VERSION ""

NS_ :

BS_:

BU_: NUC IPC VCU ADCU Mobileye Instrumentation Vehicle ESR
VAL_TABLE_ VtSIg_eventState_9 9 "caution-Conflicting-Traffic" 8 "protected-clearance : yellow" 7 "permissive-clearance" 6 "protected-Movement-Allowed" 5 "permissive-Movement-Allowed" 4 "pre-Movement : red+yellow partly" 3 "stop-And-Remain : red right" 2 "stop-Then-Proceed : flashing red" 1 "dark" 0 "unavailable" ;
VAL_TABLE_ VtSIg_eventState_8 9 "caution-Conflicting-Traffic" 8 "protected-clearance : yellow" 7 "permissive-clearance" 6 "protected-Movement-Allowed" 5 "permissive-Movement-Allowed" 4 "pre-Movement : red+yellow partly" 3 "stop-And-Remain : red right" 2 "stop-Then-Proceed : flashing red" 1 "dark" 0 "unavailable" ;
VAL_TABLE_ VtSIg_eventState_7 9 "caution-Conflicting-Traffic" 8 "protected-clearance : yellow" 7 "permissive-clearance" 6 "protected-Movement-Allowed" 5 "permissive-Movement-Allowed" 4 "pre-Movement : red+yellow partly" 3 "stop-And-Remain : red right" 2 "stop-Then-Proceed : flashing red" 1 "dark" 0 "unavailable" ;
VAL_TABLE_ VtSIg_eventState_6 9 "caution-Conflicting-Traffic" 8 "protected-clearance : yellow" 7 "permissive-clearance" 6 "protected-Movement-Allowed" 5 "permissive-Movement-Allowed" 4 "pre-Movement : red+yellow partly" 3 "stop-And-Remain : red right" 2 "stop-Then-Proceed : flashing red" 1 "dark" 0 "unavailable" ;
VAL_TABLE_ VtSIg_eventState_5 9 "caution-Conflicting-Traffic" 8 "protected-clearance : yellow" 7 "permissive-clearance" 6 "protected-Movement-Allowed" 5 "permissive-Movement-Allowed" 4 "pre-Movement : red+yellow partly" 3 "stop-And-Remain : red right" 2 "stop-Then-Proceed : flashing red" 1 "dark" 0 "unavailable" ;
VAL_TABLE_ VtSIg_eventState_4 9 "caution-Conflicting-Traffic" 8 "protected-clearance : yellow" 7 "permissive-clearance" 6 "protected-Movement-Allowed" 5 "permissive-Movement-Allowed" 4 "pre-Movement : red+yellow partly" 3 "stop-And-Remain : red right" 2 "stop-Then-Proceed : flashing red" 1 "dark" 0 "unavailable" ;
VAL_TABLE_ VtSIg_eventState_3 9 "caution-Conflicting-Traffic" 8 "protected-clearance : yellow" 7 "permissive-clearance" 6 "protected-Movement-Allowed" 5 "permissive-Movement-Allowed" 4 "pre-Movement : red+yellow partly" 3 "stop-And-Remain : red right" 2 "stop-Then-Proceed : flashing red" 1 "dark" 0 "unavailable" ;
VAL_TABLE_ VtSIg_eventState_2 9 "caution-Conflicting-Traffic" 8 "protected-clearance : yellow" 7 "permissive-clearance" 6 "protected-Movement-Allowed" 5 "permissive-Movement-Allowed" 4 "pre-Movement : red+yellow partly" 3 "stop-And-Remain : red right" 2 "stop-Then-Proceed : flashing red" 1 "dark" 0 "unavailable" ;
VAL_TABLE_ VtSIg_eventState_1 9 "caution-Conflicting-Traffic" 8 "protected-clearance : yellow" 7 "permissive-clearance" 6 "protected-Movement-Allowed" 5 "permissive-Movement-Allowed" 4 "pre-Movement : red+yellow partly" 3 "stop-And-Remain : red right" 2 "stop-Then-Proceed : flashing red" 1 "dark" 0 "unavailable" ;
VAL_TABLE_ Value_Table_Track_Status 7 "New Coasting Target" 6 "Invalid Coasting Target" 5 "Merged Target" 4 "Coasting Target" 3 "Updated Target" 2 "New Updated Target" 1 "New Target" 0 "No Target" ;

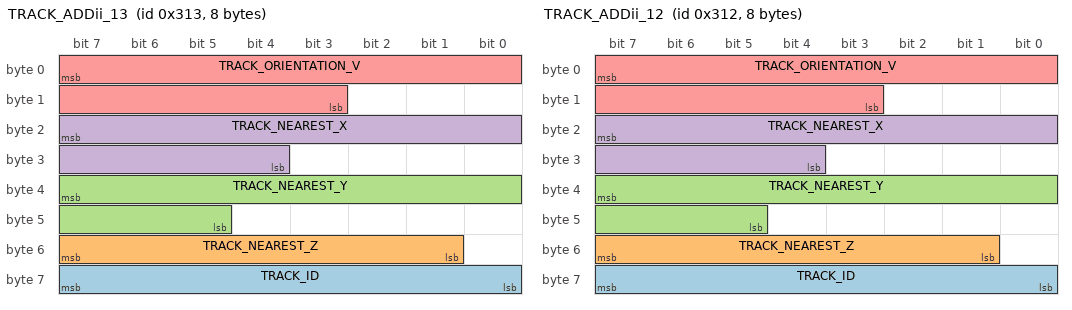
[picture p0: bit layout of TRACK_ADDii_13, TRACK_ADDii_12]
BO_ 787 TRACK_ADDii_13: 8 NUC
 SG_ TRACK_ID : 63|8@0+ (1,0) [0|0] "" Vector__XXX
 SG_ TRACK_NEAREST_Z : 55|7@0- (0.1,0) [-6.4|6.3] "m" Vector__XXX
 SG_ TRACK_NEAREST_Y : 39|11@0- (0.04,0) [-40.9|40.9] "m" Vector__XXX
 SG_ TRACK_NEAREST_X : 23|12@0- (0.1,0) [-204.8|204.7] "m" Vector__XXX
 SG_ TRACK_ORIENTATION_V : 7|13@0- (0.002,0) [-8.192|8.19] "rad" Vector__XXX

BO_ 786 TRACK_ADDii_12: 8 NUC
 SG_ TRACK_ID : 63|8@0+ (1,0) [0|0] "" Vector__XXX
 SG_ TRACK_NEAREST_Z : 55|7@0- (0.1,0) [-6.4|6.3] "m" Vector__XXX
 SG_ TRACK_NEAREST_Y : 39|11@0- (0.04,0) [-40.9|40.9] "m" Vector__XXX
 SG_ TRACK_NEAREST_X : 23|12@0- (0.1,0) [-204.8|204.7] "m" Vector__XXX
 SG_ TRACK_ORIENTATION_V : 7|13@0- (0.002,0) [-8.192|8.19] "rad" Vector__XXX

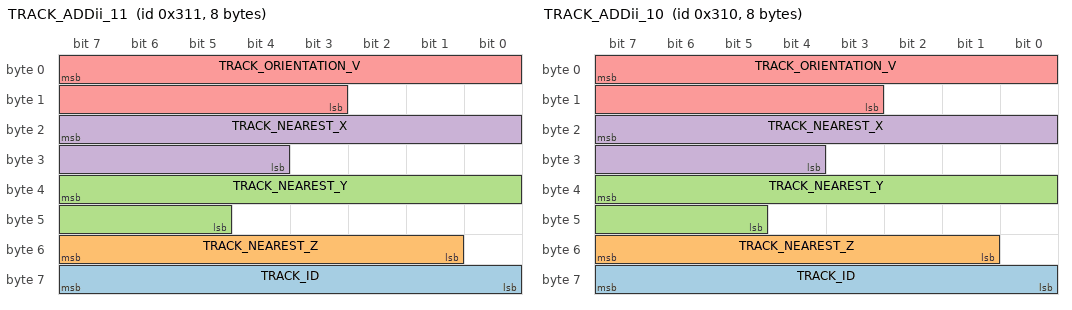
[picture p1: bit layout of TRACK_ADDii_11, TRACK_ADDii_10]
BO_ 785 TRACK_ADDii_11: 8 NUC
 SG_ TRACK_ID : 63|8@0+ (1,0) [0|0] "" Vector__XXX
 SG_ TRACK_NEAREST_Z : 55|7@0- (0.1,0) [-6.4|6.3] "m" Vector__XXX
 SG_ TRACK_NEAREST_Y : 39|11@0- (0.04,0) [-40.9|40.9] "m" Vector__XXX
 SG_ TRACK_NEAREST_X : 23|12@0- (0.1,0) [-204.8|204.7] "m" Vector__XXX
 SG_ TRACK_ORIENTATION_V : 7|13@0- (0.002,0) [-8.192|8.19] "rad" Vector__XXX

BO_ 784 TRACK_ADDii_10: 8 NUC
 SG_ TRACK_ID : 63|8@0+ (1,0) [0|0] "" Vector__XXX
 SG_ TRACK_NEAREST_Z : 55|7@0- (0.1,0) [-6.4|6.3] "m" Vector__XXX
 SG_ TRACK_NEAREST_Y : 39|11@0- (0.04,0) [-40.9|40.9] "m" Vector__XXX
 SG_ TRACK_NEAREST_X : 23|12@0- (0.1,0) [-204.8|204.7] "m" Vector__XXX
 SG_ TRACK_ORIENTATION_V : 7|13@0- (0.002,0) [-8.192|8.19] "rad" Vector__XXX

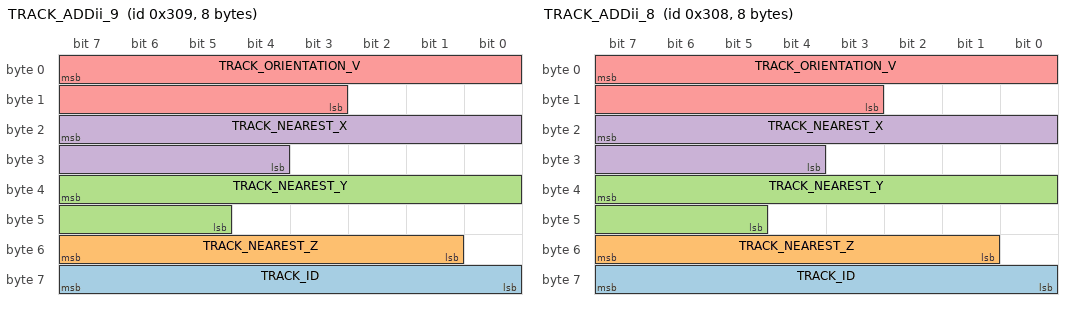
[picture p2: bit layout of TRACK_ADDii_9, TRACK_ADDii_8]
BO_ 777 TRACK_ADDii_9: 8 NUC
 SG_ TRACK_ID : 63|8@0+ (1,0) [0|0] "" Vector__XXX
 SG_ TRACK_NEAREST_Z : 55|7@0- (0.1,0) [-6.4|6.3] "m" Vector__XXX
 SG_ TRACK_NEAREST_Y : 39|11@0- (0.04,0) [-40.9|40.9] "m" Vector__XXX
 SG_ TRACK_NEAREST_X : 23|12@0- (0.1,0) [-204.8|204.7] "m" Vector__XXX
 SG_ TRACK_ORIENTATION_V : 7|13@0- (0.002,0) [-8.192|8.19] "rad" Vector__XXX

BO_ 776 TRACK_ADDii_8: 8 NUC
 SG_ TRACK_ID : 63|8@0+ (1,0) [0|0] "" Vector__XXX
 SG_ TRACK_NEAREST_Z : 55|7@0- (0.1,0) [-6.4|6.3] "m" Vector__XXX
 SG_ TRACK_NEAREST_Y : 39|11@0- (0.04,0) [-40.9|40.9] "m" Vector__XXX
 SG_ TRACK_NEAREST_X : 23|12@0- (0.1,0) [-204.8|204.7] "m" Vector__XXX
 SG_ TRACK_ORIENTATION_V : 7|13@0- (0.002,0) [-8.192|8.19] "rad" Vector__XXX

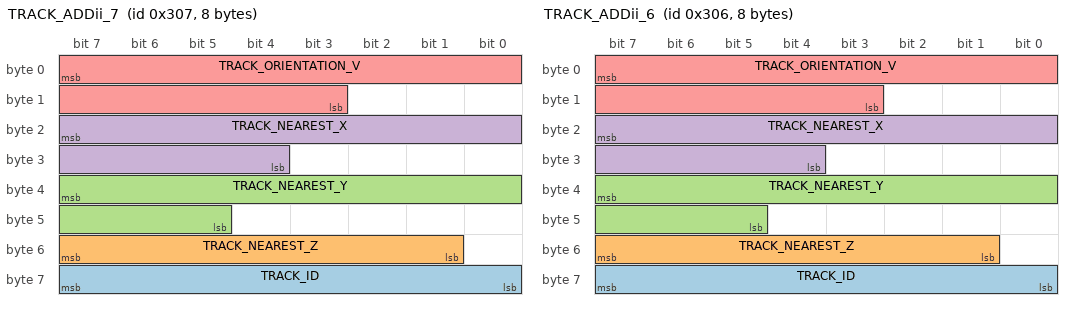
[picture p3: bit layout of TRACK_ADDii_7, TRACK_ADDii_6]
BO_ 775 TRACK_ADDii_7: 8 NUC
 SG_ TRACK_ID : 63|8@0+ (1,0) [0|0] "" Vector__XXX
 SG_ TRACK_NEAREST_Z : 55|7@0- (0.1,0) [-6.4|6.3] "m" Vector__XXX
 SG_ TRACK_NEAREST_Y : 39|11@0- (0.04,0) [-40.9|40.9] "m" Vector__XXX
 SG_ TRACK_NEAREST_X : 23|12@0- (0.1,0) [-204.8|204.7] "m" Vector__XXX
 SG_ TRACK_ORIENTATION_V : 7|13@0- (0.002,0) [-8.192|8.19] "rad" Vector__XXX

BO_ 774 TRACK_ADDii_6: 8 NUC
 SG_ TRACK_ID : 63|8@0+ (1,0) [0|0] "" Vector__XXX
 SG_ TRACK_NEAREST_Z : 55|7@0- (0.1,0) [-6.4|6.3] "m" Vector__XXX
 SG_ TRACK_NEAREST_Y : 39|11@0- (0.04,0) [-40.9|40.9] "m" Vector__XXX
 SG_ TRACK_NEAREST_X : 23|12@0- (0.1,0) [-204.8|204.7] "m" Vector__XXX
 SG_ TRACK_ORIENTATION_V : 7|13@0- (0.002,0) [-8.192|8.19] "rad" Vector__XXX

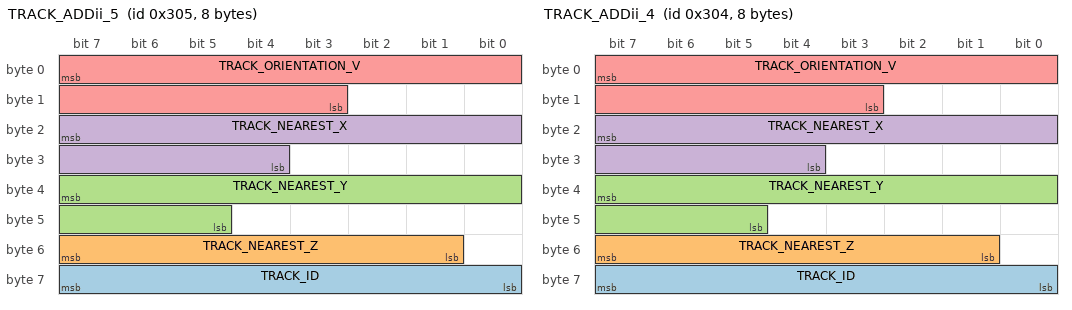
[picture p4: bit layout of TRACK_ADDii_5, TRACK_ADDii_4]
BO_ 773 TRACK_ADDii_5: 8 NUC
 SG_ TRACK_ID : 63|8@0+ (1,0) [0|0] "" Vector__XXX
 SG_ TRACK_NEAREST_Z : 55|7@0- (0.1,0) [-6.4|6.3] "m" Vector__XXX
 SG_ TRACK_NEAREST_Y : 39|11@0- (0.04,0) [-40.9|40.9] "m" Vector__XXX
 SG_ TRACK_NEAREST_X : 23|12@0- (0.1,0) [-204.8|204.7] "m" Vector__XXX
 SG_ TRACK_ORIENTATION_V : 7|13@0- (0.002,0) [-8.192|8.19] "rad" Vector__XXX

BO_ 772 TRACK_ADDii_4: 8 NUC
 SG_ TRACK_ID : 63|8@0+ (1,0) [0|0] "" Vector__XXX
 SG_ TRACK_NEAREST_Z : 55|7@0- (0.1,0) [-6.4|6.3] "m" Vector__XXX
 SG_ TRACK_NEAREST_Y : 39|11@0- (0.04,0) [-40.9|40.9] "m" Vector__XXX
 SG_ TRACK_NEAREST_X : 23|12@0- (0.1,0) [-204.8|204.7] "m" Vector__XXX
 SG_ TRACK_ORIENTATION_V : 7|13@0- (0.002,0) [-8.192|8.19] "rad" Vector__XXX

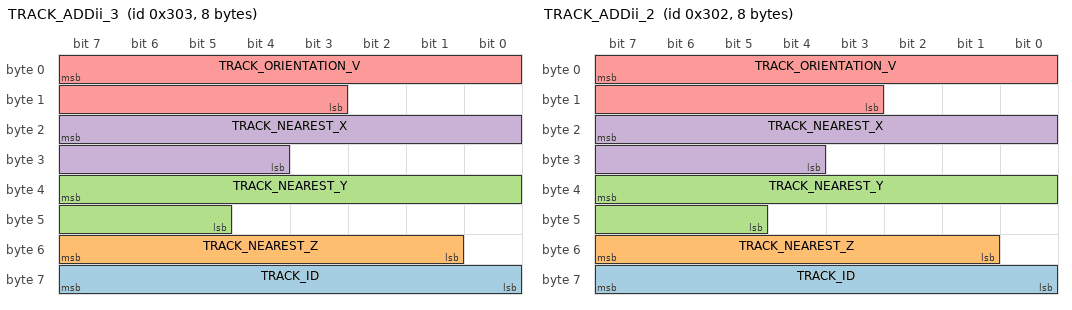
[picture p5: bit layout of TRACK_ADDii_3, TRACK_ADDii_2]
BO_ 771 TRACK_ADDii_3: 8 NUC
 SG_ TRACK_ID : 63|8@0+ (1,0) [0|0] "" Vector__XXX
 SG_ TRACK_NEAREST_Z : 55|7@0- (0.1,0) [-6.4|6.3] "m" Vector__XXX
 SG_ TRACK_NEAREST_Y : 39|11@0- (0.04,0) [-40.9|40.9] "m" Vector__XXX
 SG_ TRACK_NEAREST_X : 23|12@0- (0.1,0) [-204.8|204.7] "m" Vector__XXX
 SG_ TRACK_ORIENTATION_V : 7|13@0- (0.002,0) [-8.192|8.19] "rad" Vector__XXX

BO_ 770 TRACK_ADDii_2: 8 NUC
 SG_ TRACK_ID : 63|8@0+ (1,0) [0|0] "" Vector__XXX
 SG_ TRACK_NEAREST_Z : 55|7@0- (0.1,0) [-6.4|6.3] "m" Vector__XXX
 SG_ TRACK_NEAREST_Y : 39|11@0- (0.04,0) [-40.9|40.9] "m" Vector__XXX
 SG_ TRACK_NEAREST_X : 23|12@0- (0.1,0) [-204.8|204.7] "m" Vector__XXX
 SG_ TRACK_ORIENTATION_V : 7|13@0- (0.002,0) [-8.192|8.19] "rad" Vector__XXX

BO_ 769 TRACK_ADDii_1: 8 NUC
 SG_ TRACK_ID : 63|8@0+ (1,0) [0|0] "" Vector__XXX
 SG_ TRACK_NEAREST_Z : 55|7@0- (0.1,0) [-6.4|6.3] "m" Vector__XXX
 SG_ TRACK_NEAREST_Y : 39|11@0- (0.04,0) [-40.9|40.9] "m" Vector__XXX
 SG_ TRACK_NEAREST_X : 23|12@0- (0.1,0) [-204.8|204.7] "m" Vector__XXX
 SG_ TRACK_ORIENTATION_V : 7|13@0- (0.002,0) [-8.192|8.19] "rad" Vector__XXX

BO_ 768 TRACK_ADDii_0: 8 NUC
 SG_ TRACK_ID : 63|8@0+ (1,0) [0|0] "" Vector__XXX
 SG_ TRACK_NEAREST_Z : 55|7@0- (0.1,0) [-6.4|6.3] "m" Vector__XXX
 SG_ TRACK_NEAREST_Y : 39|11@0- (0.04,0) [-40.9|40.9] "m" Vector__XXX
 SG_ TRACK_NEAREST_X : 23|12@0- (0.1,0) [-204.8|204.7] "m" Vector__XXX
 SG_ TRACK_ORIENTATION_V : 7|13@0- (0.002,0) [-8.192|8.19] "rad" Vector__XXX

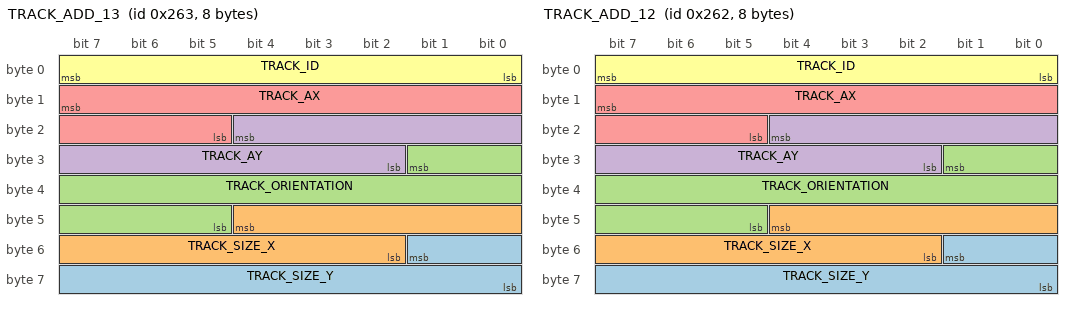
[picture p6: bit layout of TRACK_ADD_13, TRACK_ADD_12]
BO_ 611 TRACK_ADD_13: 8 NUC
 SG_ TRACK_SIZE_Y : 49|10@0+ (0.01,0) [0|10.23] "m" Vector__XXX
 SG_ TRACK_SIZE_X : 44|11@0+ (0.01,0) [0|20.47] "m" Vector__XXX
 SG_ TRACK_ORIENTATION : 25|13@0- (0.002,0) [-8.192|8.19] "rad" Vector__XXX
 SG_ TRACK_AY : 20|11@0- (0.01,0) [-10.24|10.23] "m/s^2" Vector__XXX
 SG_ TRACK_AX : 15|11@0- (0.01,0) [-10.24|10.23] "m/s^2" Vector__XXX
 SG_ TRACK_ID : 7|8@0+ (1,0) [0|255] "" Vector__XXX

BO_ 610 TRACK_ADD_12: 8 NUC
 SG_ TRACK_SIZE_Y : 49|10@0+ (0.01,0) [0|10.23] "m" Vector__XXX
 SG_ TRACK_SIZE_X : 44|11@0+ (0.01,0) [0|20.47] "m" Vector__XXX
 SG_ TRACK_ORIENTATION : 25|13@0- (0.002,0) [-8.192|8.19] "rad" Vector__XXX
 SG_ TRACK_AY : 20|11@0- (0.01,0) [-10.24|10.23] "m/s^2" Vector__XXX
 SG_ TRACK_AX : 15|11@0- (0.01,0) [-10.24|10.23] "m/s^2" Vector__XXX
 SG_ TRACK_ID : 7|8@0+ (1,0) [0|255] "" Vector__XXX

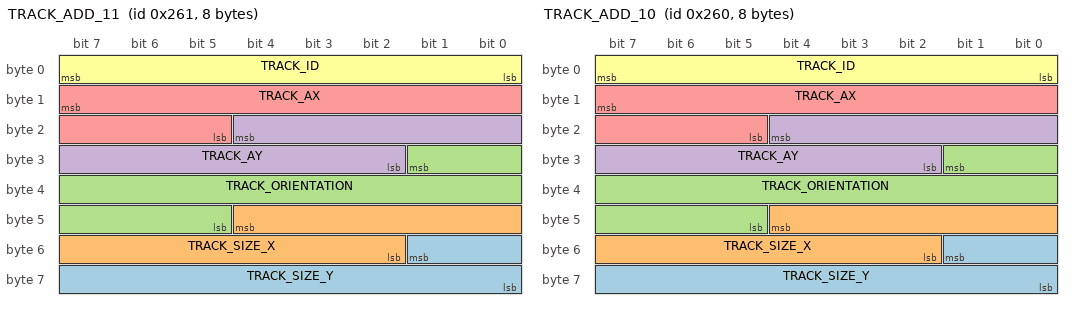
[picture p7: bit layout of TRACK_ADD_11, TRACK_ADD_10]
BO_ 609 TRACK_ADD_11: 8 NUC
 SG_ TRACK_SIZE_Y : 49|10@0+ (0.01,0) [0|10.23] "m" Vector__XXX
 SG_ TRACK_SIZE_X : 44|11@0+ (0.01,0) [0|20.47] "m" Vector__XXX
 SG_ TRACK_ORIENTATION : 25|13@0- (0.002,0) [-8.192|8.19] "rad" Vector__XXX
 SG_ TRACK_AY : 20|11@0- (0.01,0) [-10.24|10.23] "m/s^2" Vector__XXX
 SG_ TRACK_AX : 15|11@0- (0.01,0) [-10.24|10.23] "m/s^2" Vector__XXX
 SG_ TRACK_ID : 7|8@0+ (1,0) [0|255] "" Vector__XXX

BO_ 608 TRACK_ADD_10: 8 NUC
 SG_ TRACK_SIZE_Y : 49|10@0+ (0.01,0) [0|10.23] "m" Vector__XXX
 SG_ TRACK_SIZE_X : 44|11@0+ (0.01,0) [0|20.47] "m" Vector__XXX
 SG_ TRACK_ORIENTATION : 25|13@0- (0.002,0) [-8.192|8.19] "rad" Vector__XXX
 SG_ TRACK_AY : 20|11@0- (0.01,0) [-10.24|10.23] "m/s^2" Vector__XXX
 SG_ TRACK_AX : 15|11@0- (0.01,0) [-10.24|10.23] "m/s^2" Vector__XXX
 SG_ TRACK_ID : 7|8@0+ (1,0) [0|255] "" Vector__XXX

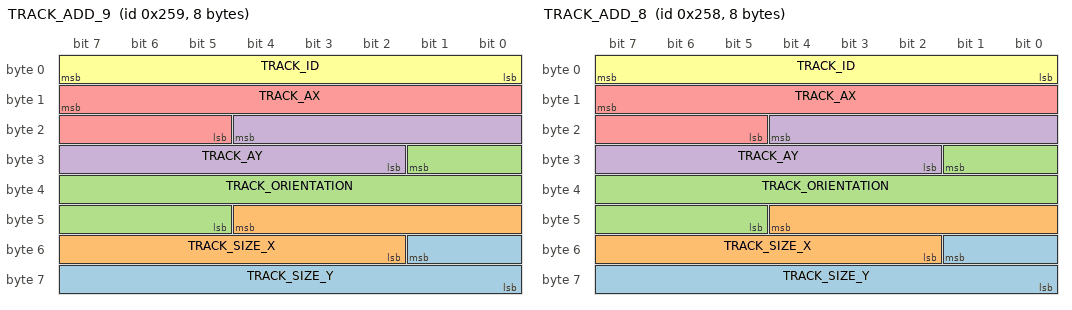
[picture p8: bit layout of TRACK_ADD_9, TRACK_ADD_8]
BO_ 601 TRACK_ADD_9: 8 NUC
 SG_ TRACK_SIZE_Y : 49|10@0+ (0.01,0) [0|10.23] "m" Vector__XXX
 SG_ TRACK_SIZE_X : 44|11@0+ (0.01,0) [0|20.47] "m" Vector__XXX
 SG_ TRACK_ORIENTATION : 25|13@0- (0.002,0) [-8.192|8.19] "rad" Vector__XXX
 SG_ TRACK_AY : 20|11@0- (0.01,0) [-10.24|10.23] "m/s^2" Vector__XXX
 SG_ TRACK_AX : 15|11@0- (0.01,0) [-10.24|10.23] "m/s^2" Vector__XXX
 SG_ TRACK_ID : 7|8@0+ (1,0) [0|255] "" Vector__XXX

BO_ 600 TRACK_ADD_8: 8 NUC
 SG_ TRACK_SIZE_Y : 49|10@0+ (0.01,0) [0|10.23] "m" Vector__XXX
 SG_ TRACK_SIZE_X : 44|11@0+ (0.01,0) [0|20.47] "m" Vector__XXX
 SG_ TRACK_ORIENTATION : 25|13@0- (0.002,0) [-8.192|8.19] "rad" Vector__XXX
 SG_ TRACK_AY : 20|11@0- (0.01,0) [-10.24|10.23] "m/s^2" Vector__XXX
 SG_ TRACK_AX : 15|11@0- (0.01,0) [-10.24|10.23] "m/s^2" Vector__XXX
 SG_ TRACK_ID : 7|8@0+ (1,0) [0|255] "" Vector__XXX

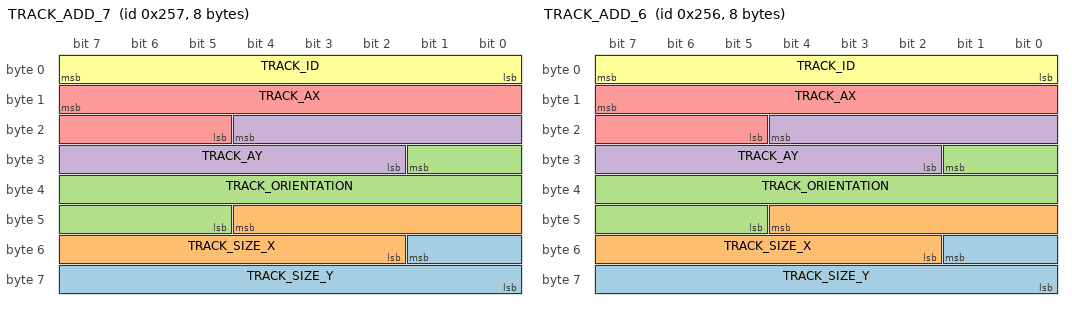
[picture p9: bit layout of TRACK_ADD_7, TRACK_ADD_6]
BO_ 599 TRACK_ADD_7: 8 NUC
 SG_ TRACK_SIZE_Y : 49|10@0+ (0.01,0) [0|10.23] "m" Vector__XXX
 SG_ TRACK_SIZE_X : 44|11@0+ (0.01,0) [0|20.47] "m" Vector__XXX
 SG_ TRACK_ORIENTATION : 25|13@0- (0.002,0) [-8.192|8.19] "rad" Vector__XXX
 SG_ TRACK_AY : 20|11@0- (0.01,0) [-10.24|10.23] "m/s^2" Vector__XXX
 SG_ TRACK_AX : 15|11@0- (0.01,0) [-10.24|10.23] "m/s^2" Vector__XXX
 SG_ TRACK_ID : 7|8@0+ (1,0) [0|255] "" Vector__XXX

BO_ 598 TRACK_ADD_6: 8 NUC
 SG_ TRACK_SIZE_Y : 49|10@0+ (0.01,0) [0|10.23] "m" Vector__XXX
 SG_ TRACK_SIZE_X : 44|11@0+ (0.01,0) [0|20.47] "m" Vector__XXX
 SG_ TRACK_ORIENTATION : 25|13@0- (0.002,0) [-8.192|8.19] "rad" Vector__XXX
 SG_ TRACK_AY : 20|11@0- (0.01,0) [-10.24|10.23] "m/s^2" Vector__XXX
 SG_ TRACK_AX : 15|11@0- (0.01,0) [-10.24|10.23] "m/s^2" Vector__XXX
 SG_ TRACK_ID : 7|8@0+ (1,0) [0|255] "" Vector__XXX

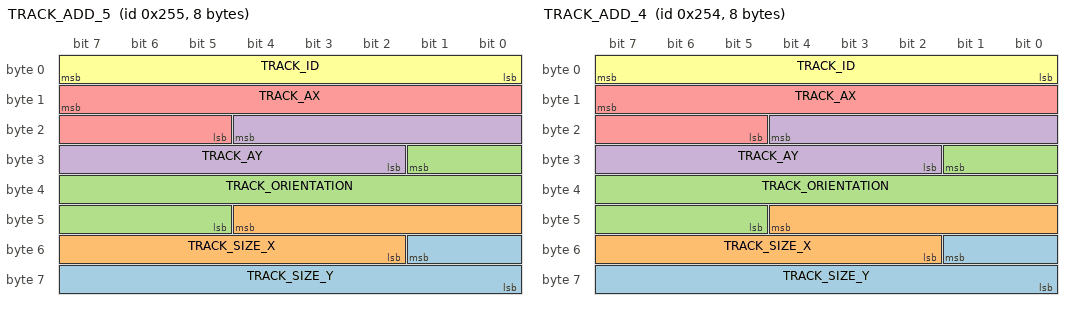
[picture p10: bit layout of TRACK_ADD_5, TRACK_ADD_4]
BO_ 597 TRACK_ADD_5: 8 NUC
 SG_ TRACK_SIZE_Y : 49|10@0+ (0.01,0) [0|10.23] "m" Vector__XXX
 SG_ TRACK_SIZE_X : 44|11@0+ (0.01,0) [0|20.47] "m" Vector__XXX
 SG_ TRACK_ORIENTATION : 25|13@0- (0.002,0) [-8.192|8.19] "rad" Vector__XXX
 SG_ TRACK_AY : 20|11@0- (0.01,0) [-10.24|10.23] "m/s^2" Vector__XXX
 SG_ TRACK_AX : 15|11@0- (0.01,0) [-10.24|10.23] "m/s^2" Vector__XXX
 SG_ TRACK_ID : 7|8@0+ (1,0) [0|255] "" Vector__XXX

BO_ 596 TRACK_ADD_4: 8 NUC
 SG_ TRACK_SIZE_Y : 49|10@0+ (0.01,0) [0|10.23] "m" Vector__XXX
 SG_ TRACK_SIZE_X : 44|11@0+ (0.01,0) [0|20.47] "m" Vector__XXX
 SG_ TRACK_ORIENTATION : 25|13@0- (0.002,0) [-8.192|8.19] "rad" Vector__XXX
 SG_ TRACK_AY : 20|11@0- (0.01,0) [-10.24|10.23] "m/s^2" Vector__XXX
 SG_ TRACK_AX : 15|11@0- (0.01,0) [-10.24|10.23] "m/s^2" Vector__XXX
 SG_ TRACK_ID : 7|8@0+ (1,0) [0|255] "" Vector__XXX

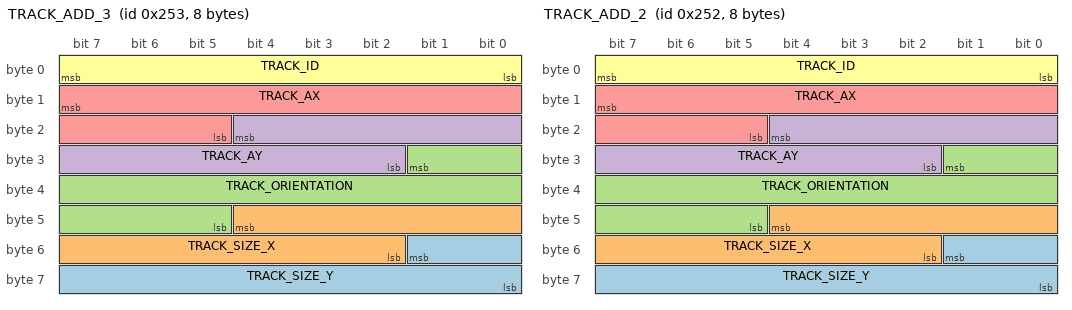
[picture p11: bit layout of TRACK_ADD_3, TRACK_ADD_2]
BO_ 595 TRACK_ADD_3: 8 NUC
 SG_ TRACK_SIZE_Y : 49|10@0+ (0.01,0) [0|10.23] "m" Vector__XXX
 SG_ TRACK_SIZE_X : 44|11@0+ (0.01,0) [0|20.47] "m" Vector__XXX
 SG_ TRACK_ORIENTATION : 25|13@0- (0.002,0) [-8.192|8.19] "rad" Vector__XXX
 SG_ TRACK_AY : 20|11@0- (0.01,0) [-10.24|10.23] "m/s^2" Vector__XXX
 SG_ TRACK_AX : 15|11@0- (0.01,0) [-10.24|10.23] "m/s^2" Vector__XXX
 SG_ TRACK_ID : 7|8@0+ (1,0) [0|255] "" Vector__XXX

BO_ 594 TRACK_ADD_2: 8 NUC
 SG_ TRACK_SIZE_Y : 49|10@0+ (0.01,0) [0|10.23] "m" Vector__XXX
 SG_ TRACK_SIZE_X : 44|11@0+ (0.01,0) [0|20.47] "m" Vector__XXX
 SG_ TRACK_ORIENTATION : 25|13@0- (0.002,0) [-8.192|8.19] "rad" Vector__XXX
 SG_ TRACK_AY : 20|11@0- (0.01,0) [-10.24|10.23] "m/s^2" Vector__XXX
 SG_ TRACK_AX : 15|11@0- (0.01,0) [-10.24|10.23] "m/s^2" Vector__XXX
 SG_ TRACK_ID : 7|8@0+ (1,0) [0|255] "" Vector__XXX

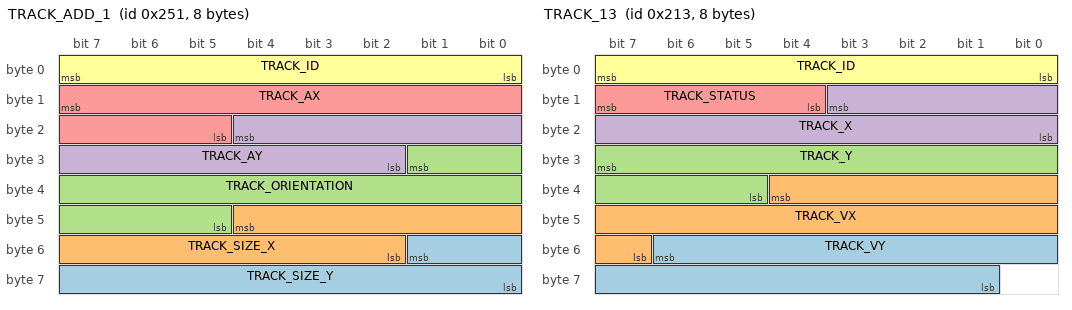
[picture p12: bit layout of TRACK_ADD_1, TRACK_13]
BO_ 593 TRACK_ADD_1: 8 NUC
 SG_ TRACK_SIZE_Y : 49|10@0+ (0.01,0) [0|10.23] "m" Vector__XXX
 SG_ TRACK_SIZE_X : 44|11@0+ (0.01,0) [0|20.47] "m" Vector__XXX
 SG_ TRACK_ORIENTATION : 25|13@0- (0.002,0) [-8.192|8.19] "rad" Vector__XXX
 SG_ TRACK_AY : 20|11@0- (0.01,0) [-10.24|10.23] "m/s^2" Vector__XXX
 SG_ TRACK_AX : 15|11@0- (0.01,0) [-10.24|10.23] "m/s^2" Vector__XXX
 SG_ TRACK_ID : 7|8@0+ (1,0) [0|255] "" Vector__XXX

BO_ 531 TRACK_13: 8 NUC
 SG_ TRACK_VY : 54|14@0- (0.01,0) [-81.92|81.91] "m/s" Vector__XXX
 SG_ TRACK_VX : 36|14@0- (0.01,0) [-81.92|81.91] "m/s" Vector__XXX
 SG_ TRACK_Y : 31|11@0- (0.04,0) [-40.9|40.9] "m" Vector__XXX
 SG_ TRACK_X : 11|12@0- (0.1,0) [-204.8|204.7] "m" Vector__XXX
 SG_ TRACK_STATUS : 15|4@0+ (1,0) [0|0] "" Vector__XXX
 SG_ TRACK_ID : 7|8@0+ (1,0) [0|255] "" Vector__XXX

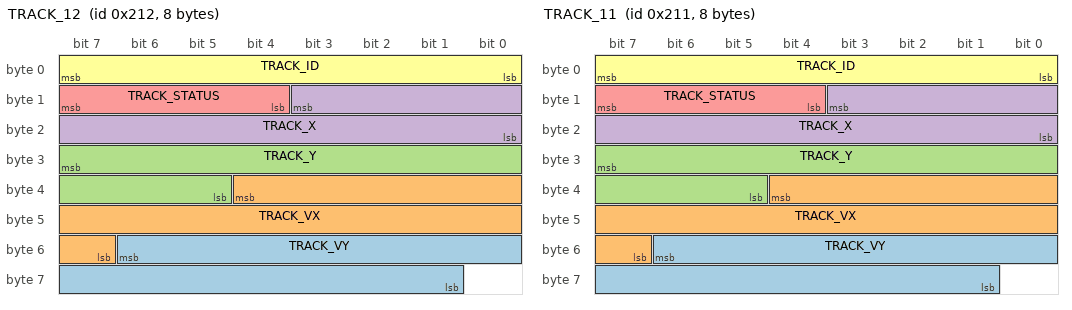
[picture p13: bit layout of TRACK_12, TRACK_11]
BO_ 530 TRACK_12: 8 NUC
 SG_ TRACK_VY : 54|14@0- (0.01,0) [-81.92|81.91] "m/s" Vector__XXX
 SG_ TRACK_VX : 36|14@0- (0.01,0) [-81.92|81.91] "m/s" Vector__XXX
 SG_ TRACK_Y : 31|11@0- (0.04,0) [-40.9|40.9] "m" Vector__XXX
 SG_ TRACK_X : 11|12@0- (0.1,0) [-204.8|204.7] "m" Vector__XXX
 SG_ TRACK_STATUS : 15|4@0+ (1,0) [0|0] "" Vector__XXX
 SG_ TRACK_ID : 7|8@0+ (1,0) [0|255] "" Vector__XXX

BO_ 529 TRACK_11: 8 NUC
 SG_ TRACK_VY : 54|14@0- (0.01,0) [-81.92|81.91] "m/s" Vector__XXX
 SG_ TRACK_VX : 36|14@0- (0.01,0) [-81.92|81.91] "m/s" Vector__XXX
 SG_ TRACK_Y : 31|11@0- (0.04,0) [-40.9|40.9] "m" Vector__XXX
 SG_ TRACK_X : 11|12@0- (0.1,0) [-204.8|204.7] "m" Vector__XXX
 SG_ TRACK_STATUS : 15|4@0+ (1,0) [0|0] "" Vector__XXX
 SG_ TRACK_ID : 7|8@0+ (1,0) [0|255] "" Vector__XXX

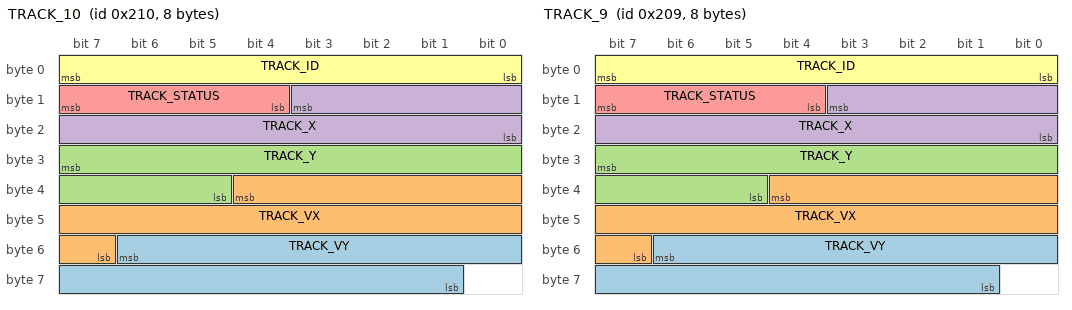
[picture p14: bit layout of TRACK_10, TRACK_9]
BO_ 528 TRACK_10: 8 NUC
 SG_ TRACK_VY : 54|14@0- (0.01,0) [-81.92|81.91] "m/s" Vector__XXX
 SG_ TRACK_VX : 36|14@0- (0.01,0) [-81.92|81.91] "m/s" Vector__XXX
 SG_ TRACK_Y : 31|11@0- (0.04,0) [-40.9|40.9] "m" Vector__XXX
 SG_ TRACK_X : 11|12@0- (0.1,0) [-204.8|204.7] "m" Vector__XXX
 SG_ TRACK_STATUS : 15|4@0+ (1,0) [0|0] "" Vector__XXX
 SG_ TRACK_ID : 7|8@0+ (1,0) [0|255] "" Vector__XXX

BO_ 521 TRACK_9: 8 NUC
 SG_ TRACK_VY : 54|14@0- (0.01,0) [-81.92|81.91] "m/s" Vector__XXX
 SG_ TRACK_VX : 36|14@0- (0.01,0) [-81.92|81.91] "m/s" Vector__XXX
 SG_ TRACK_Y : 31|11@0- (0.04,0) [-40.9|40.9] "m" Vector__XXX
 SG_ TRACK_X : 11|12@0- (0.1,0) [-204.8|204.7] "m" Vector__XXX
 SG_ TRACK_STATUS : 15|4@0+ (1,0) [0|0] "" Vector__XXX
 SG_ TRACK_ID : 7|8@0+ (1,0) [0|255] "" Vector__XXX

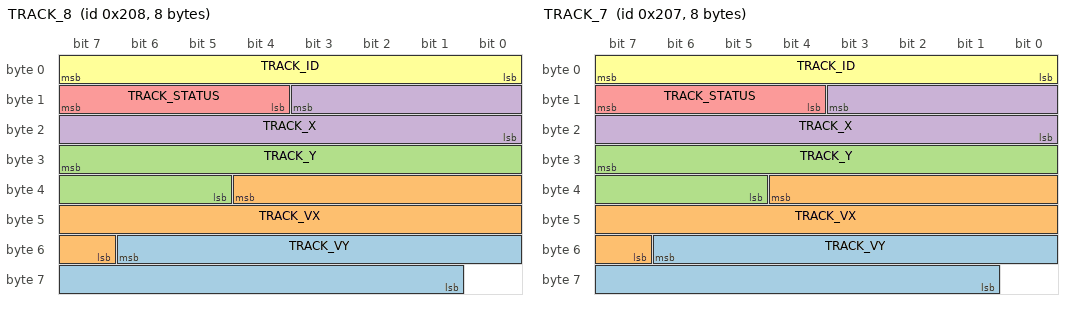
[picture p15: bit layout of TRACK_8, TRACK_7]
BO_ 520 TRACK_8: 8 NUC
 SG_ TRACK_VY : 54|14@0- (0.01,0) [-81.92|81.91] "m/s" Vector__XXX
 SG_ TRACK_VX : 36|14@0- (0.01,0) [-81.92|81.91] "m/s" Vector__XXX
 SG_ TRACK_Y : 31|11@0- (0.04,0) [-40.9|40.9] "m" Vector__XXX
 SG_ TRACK_X : 11|12@0- (0.1,0) [-204.8|204.7] "m" Vector__XXX
 SG_ TRACK_STATUS : 15|4@0+ (1,0) [0|0] "" Vector__XXX
 SG_ TRACK_ID : 7|8@0+ (1,0) [0|255] "" Vector__XXX

BO_ 519 TRACK_7: 8 NUC
 SG_ TRACK_VY : 54|14@0- (0.01,0) [-81.92|81.91] "m/s" Vector__XXX
 SG_ TRACK_VX : 36|14@0- (0.01,0) [-81.92|81.91] "m/s" Vector__XXX
 SG_ TRACK_Y : 31|11@0- (0.04,0) [-40.9|40.9] "m" Vector__XXX
 SG_ TRACK_X : 11|12@0- (0.1,0) [-204.8|204.7] "m" Vector__XXX
 SG_ TRACK_STATUS : 15|4@0+ (1,0) [0|0] "" Vector__XXX
 SG_ TRACK_ID : 7|8@0+ (1,0) [0|255] "" Vector__XXX

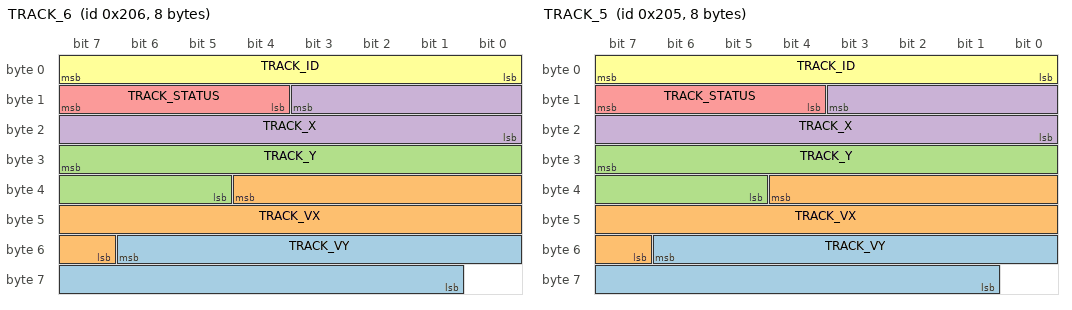
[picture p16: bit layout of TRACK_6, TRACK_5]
BO_ 518 TRACK_6: 8 NUC
 SG_ TRACK_VY : 54|14@0- (0.01,0) [-81.92|81.91] "m/s" Vector__XXX
 SG_ TRACK_VX : 36|14@0- (0.01,0) [-81.92|81.91] "m/s" Vector__XXX
 SG_ TRACK_Y : 31|11@0- (0.04,0) [-40.9|40.9] "m" Vector__XXX
 SG_ TRACK_X : 11|12@0- (0.1,0) [-204.8|204.7] "m" Vector__XXX
 SG_ TRACK_STATUS : 15|4@0+ (1,0) [0|0] "" Vector__XXX
 SG_ TRACK_ID : 7|8@0+ (1,0) [0|255] "" Vector__XXX

BO_ 517 TRACK_5: 8 NUC
 SG_ TRACK_VY : 54|14@0- (0.01,0) [-81.92|81.91] "m/s" Vector__XXX
 SG_ TRACK_VX : 36|14@0- (0.01,0) [-81.92|81.91] "m/s" Vector__XXX
 SG_ TRACK_Y : 31|11@0- (0.04,0) [-40.9|40.9] "m" Vector__XXX
 SG_ TRACK_X : 11|12@0- (0.1,0) [-204.8|204.7] "m" Vector__XXX
 SG_ TRACK_STATUS : 15|4@0+ (1,0) [0|0] "" Vector__XXX
 SG_ TRACK_ID : 7|8@0+ (1,0) [0|255] "" Vector__XXX

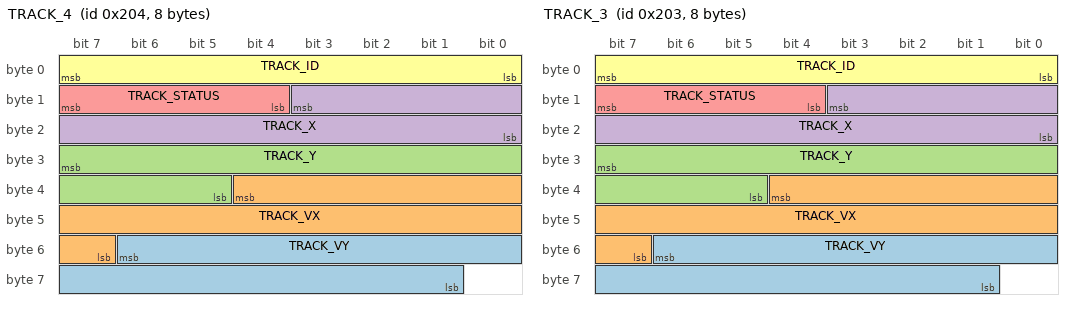
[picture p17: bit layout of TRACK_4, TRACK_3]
BO_ 516 TRACK_4: 8 NUC
 SG_ TRACK_VY : 54|14@0- (0.01,0) [-81.92|81.91] "m/s" Vector__XXX
 SG_ TRACK_VX : 36|14@0- (0.01,0) [-81.92|81.91] "m/s" Vector__XXX
 SG_ TRACK_Y : 31|11@0- (0.04,0) [-40.9|40.9] "m" Vector__XXX
 SG_ TRACK_X : 11|12@0- (0.1,0) [-204.8|204.7] "m" Vector__XXX
 SG_ TRACK_STATUS : 15|4@0+ (1,0) [0|0] "" Vector__XXX
 SG_ TRACK_ID : 7|8@0+ (1,0) [0|255] "" Vector__XXX

BO_ 515 TRACK_3: 8 NUC
 SG_ TRACK_VY : 54|14@0- (0.01,0) [-81.92|81.91] "m/s" Vector__XXX
 SG_ TRACK_VX : 36|14@0- (0.01,0) [-81.92|81.91] "m/s" Vector__XXX
 SG_ TRACK_Y : 31|11@0- (0.04,0) [-40.9|40.9] "m" Vector__XXX
 SG_ TRACK_X : 11|12@0- (0.1,0) [-204.8|204.7] "m" Vector__XXX
 SG_ TRACK_STATUS : 15|4@0+ (1,0) [0|0] "" Vector__XXX
 SG_ TRACK_ID : 7|8@0+ (1,0) [0|255] "" Vector__XXX

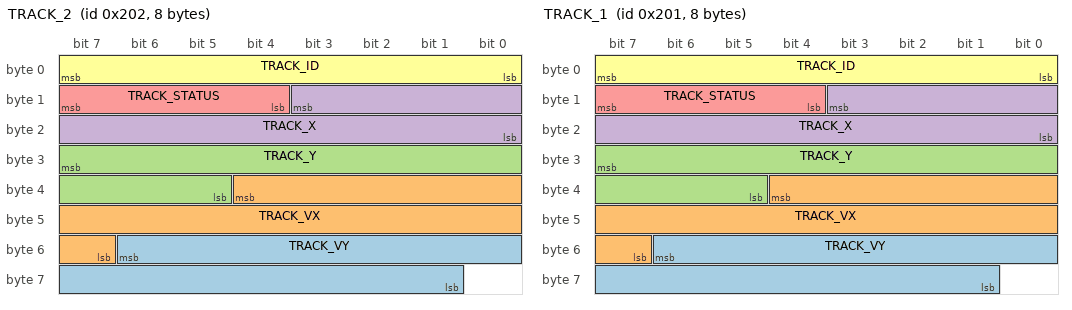
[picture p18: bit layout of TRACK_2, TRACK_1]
BO_ 514 TRACK_2: 8 NUC
 SG_ TRACK_VY : 54|14@0- (0.01,0) [-81.92|81.91] "m/s" Vector__XXX
 SG_ TRACK_VX : 36|14@0- (0.01,0) [-81.92|81.91] "m/s" Vector__XXX
 SG_ TRACK_Y : 31|11@0- (0.04,0) [-40.9|40.9] "m" Vector__XXX
 SG_ TRACK_X : 11|12@0- (0.1,0) [-204.8|204.7] "m" Vector__XXX
 SG_ TRACK_STATUS : 15|4@0+ (1,0) [0|0] "" Vector__XXX
 SG_ TRACK_ID : 7|8@0+ (1,0) [0|255] "" Vector__XXX

BO_ 513 TRACK_1: 8 NUC
 SG_ TRACK_VY : 54|14@0- (0.01,0) [-81.92|81.91] "m/s" Vector__XXX
 SG_ TRACK_VX : 36|14@0- (0.01,0) [-81.92|81.91] "m/s" Vector__XXX
 SG_ TRACK_Y : 31|11@0- (0.04,0) [-40.9|40.9] "m" Vector__XXX
 SG_ TRACK_X : 11|12@0- (0.1,0) [-204.8|204.7] "m" Vector__XXX
 SG_ TRACK_STATUS : 15|4@0+ (1,0) [0|0] "" Vector__XXX
 SG_ TRACK_ID : 7|8@0+ (1,0) [0|255] "" Vector__XXX

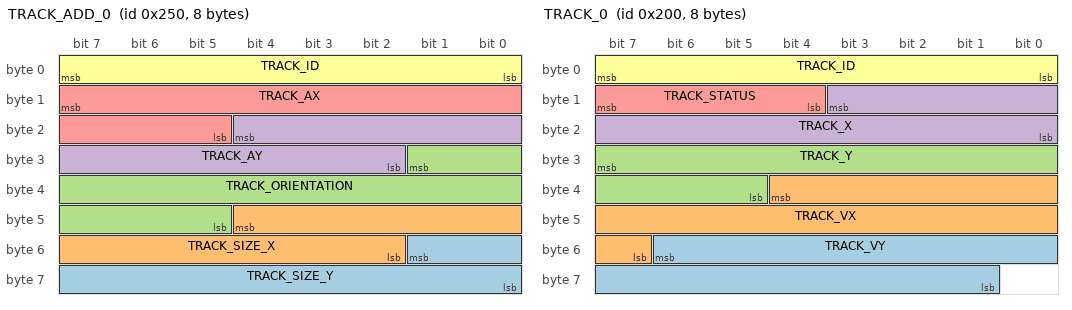
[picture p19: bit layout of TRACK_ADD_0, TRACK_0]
BO_ 592 TRACK_ADD_0: 8 NUC
 SG_ TRACK_SIZE_Y : 49|10@0+ (0.01,0) [0|10.23] "m" Vector__XXX
 SG_ TRACK_SIZE_X : 44|11@0+ (0.01,0) [0|20.47] "m" Vector__XXX
 SG_ TRACK_ORIENTATION : 25|13@0- (0.002,0) [-8.192|8.19] "rad" Vector__XXX
 SG_ TRACK_AY : 20|11@0- (0.01,0) [-10.24|10.23] "m/s^2" Vector__XXX
 SG_ TRACK_AX : 15|11@0- (0.01,0) [-10.24|10.23] "m/s^2" Vector__XXX
 SG_ TRACK_ID : 7|8@0+ (1,0) [0|255] "" Vector__XXX

BO_ 512 TRACK_0: 8 NUC
 SG_ TRACK_VY : 54|14@0- (0.01,0) [-81.92|81.91] "m/s" Vector__XXX
 SG_ TRACK_VX : 36|14@0- (0.01,0) [-81.92|81.91] "m/s" Vector__XXX
 SG_ TRACK_Y : 31|11@0- (0.04,0) [-40.9|40.9] "m" Vector__XXX
 SG_ TRACK_X : 11|12@0- (0.1,0) [-204.8|204.7] "m" Vector__XXX
 SG_ TRACK_STATUS : 15|4@0+ (1,0) [0|0] "" Vector__XXX
 SG_ TRACK_ID : 7|8@0+ (1,0) [0|255] "" Vector__XXX

CM_ "CANdb__ADEV_IONIQ__KATECH__ACAN_v10__220919.dbc Generated by EROOMAT";
BA_DEF_  "BusType" STRING ;
BA_DEF_  "ProtocolType" STRING ;
BA_DEF_ BO_  "GenMsgCycleTime" INT 0 65535;
BA_DEF_ BO_  "VFrameFormat" ENUM  "StandardCAN","ExtendedCAN","StandardCAN_FD","ExtendedCAN_FD";
BA_DEF_ SG_  "SigType" ENUM  "Default","Range","RangeSigned","ASCII","Discrete","Control","ReferencePGN","DTC","StringDelimiter","StringLength","StringLengthControl","MessageCounter","MessageChecksum";
BA_DEF_DEF_  "BusType" "CAN FD";
BA_DEF_DEF_  "ProtocolType" "CANFD";
BA_DEF_DEF_  "GenMsgCycleTime" 0;
BA_DEF_DEF_  "VFrameFormat" "StandardCAN_FD";
BA_DEF_DEF_  "SigType" "Default";
BA_ "GenMsgCycleTime" BO_ 787 100;
BA_ "GenMsgCycleTime" BO_ 786 100;
BA_ "GenMsgCycleTime" BO_ 785 100;
BA_ "GenMsgCycleTime" BO_ 784 100;
BA_ "GenMsgCycleTime" BO_ 777 100;
BA_ "GenMsgCycleTime" BO_ 776 100;
BA_ "GenMsgCycleTime" BO_ 775 100;
BA_ "GenMsgCycleTime" BO_ 774 100;
BA_ "GenMsgCycleTime" BO_ 773 100;
BA_ "GenMsgCycleTime" BO_ 772 100;
BA_ "GenMsgCycleTime" BO_ 771 100;
BA_ "GenMsgCycleTime" BO_ 770 100;
BA_ "GenMsgCycleTime" BO_ 769 100;
BA_ "GenMsgCycleTime" BO_ 768 100;
BA_ "GenMsgCycleTime" BO_ 611 10;
BA_ "GenMsgCycleTime" BO_ 610 10;
BA_ "GenMsgCycleTime" BO_ 609 10;
BA_ "GenMsgCycleTime" BO_ 608 10;
BA_ "GenMsgCycleTime" BO_ 601 10;
BA_ "GenMsgCycleTime" BO_ 600 10;
BA_ "GenMsgCycleTime" BO_ 599 10;
BA_ "GenMsgCycleTime" BO_ 598 10;
BA_ "GenMsgCycleTime" BO_ 597 10;
BA_ "GenMsgCycleTime" BO_ 596 10;
BA_ "GenMsgCycleTime" BO_ 595 10;
BA_ "GenMsgCycleTime" BO_ 594 10;
BA_ "GenMsgCycleTime" BO_ 593 10;
BA_ "GenMsgCycleTime" BO_ 531 10;
BA_ "GenMsgCycleTime" BO_ 530 10;
BA_ "GenMsgCycleTime" BO_ 529 10;
BA_ "GenMsgCycleTime" BO_ 528 10;
BA_ "GenMsgCycleTime" BO_ 521 10;
BA_ "GenMsgCycleTime" BO_ 520 10;
BA_ "GenMsgCycleTime" BO_ 519 10;
BA_ "GenMsgCycleTime" BO_ 518 10;
BA_ "GenMsgCycleTime" BO_ 517 10;
BA_ "GenMsgCycleTime" BO_ 516 10;
BA_ "GenMsgCycleTime" BO_ 515 10;
BA_ "GenMsgCycleTime" BO_ 514 10;
BA_ "GenMsgCycleTime" BO_ 513 10;
BA_ "GenMsgCycleTime" BO_ 592 10;
BA_ "GenMsgCycleTime" BO_ 512 10;
